# SN32F420 register map
Vendor: SONiX Technology Co., Ltd.; Series: SN32F420; File version: 1.00
CPU: CM0 r0p0, little endian, no MPU, no FPU, 2 interrupt priority bits
Registers are 32-bit, read-write, reset 0x0 unless marked. A register's access mark holds for its fields unless they carry their own. Offsets are from the block's base; [hi:lo] are bit positions.

## SN_SYS0 — System Control Registers 0
Base 0x40060000
0x00 ANBCTRL reset 0x1 — Offset:0x00 Analog Block Control register
  [0] IHRCEN — IHRC enable
    0=Disable IHRC; 1=Enable IHRC
0x04 PLLCTRL — Offset:0x04 PLL Control register
  [15] PLLEN — PLL enable
    0=Disable PLL; 1=Enable PLL
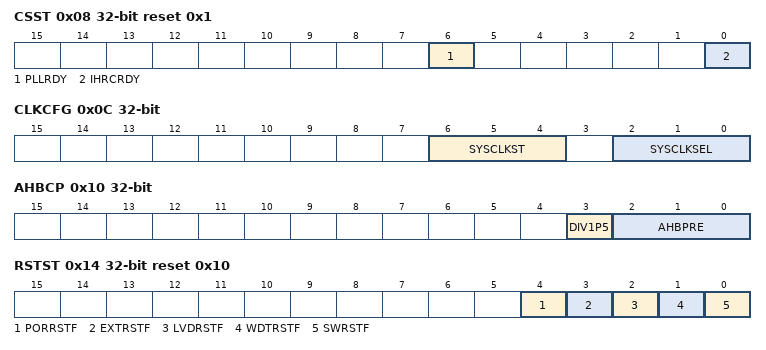
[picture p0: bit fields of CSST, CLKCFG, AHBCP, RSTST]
0x08 CSST ro reset 0x1 — Offset:0x08 Clock Source Status register
  [6] PLLRDY — PLL ready flag
    0=Not Locked (PLL is Not locked); 1=Locked (PLL is locked)
  [0] IHRCRDY — IHRC ready flag
    0=Not Ready (IHRC is Not Ready); 1=Ready (IHRC is Ready)
0x0C CLKCFG — Offset:0x0C System Clock Configuration register
  [6:4] SYSCLKST ro — System clock switch status
    0=IHRC (IHRC is used as system clock); 1=ILRC (ILRC is used as system clock); 4=PLL (PLL output is used as system clock)
  [2:0] SYSCLKSEL — System clock source selection
    0=IHRC (HCLK=IHRC); 1=ILRC (HCLK=ILRC); 4=PLL Output (HCLK=PLL output)
0x10 AHBCP — Offset:0x10 AHB Clock Prescale register
  [3] DIV1P5 — SYSCLK prescaler
    0=DIV1 (SYSCLK = SYSCLK/1); 1=DIV1P5 (SYSCLK = SYSCLK/1.5)
  [2:0] AHBPRE — AHB clock source prescaler
    0=000b (FAHB=FSYSCLK/1); 1=001b (FAHB=FSYSCLK/2); 2=010b (FAHB=FSYSCLK/4); 3=011b (FAHB=FSYSCLK/8); 4=100b (FAHB=FSYSCLK/16); 5=101b (FAHB=FSYSCLK/32); 6=110b (FAHB=FSYSCLK/64); 7=111b (FAHB=FSYSCLK/128)
0x14 RSTST reset 0x10 — Offset:0x14 System Reset Status register
  [4] PORRSTF — POR reset flag
    0=None (No POR occurred); 1=POR (POR occurred)
  [3] EXTRSTF — External reset flag
    0=None (No Extenral reset occurred); 1=External reset occurred
  [2] LVDRSTF — LVD reset flag
    0=None (No LVD reset occurred); 1=LVD reset occurred
  [1] WDTRSTF — WDT reset flag
    0=None (No WDT reset occurred); 1=WDR reset (WDT reset occurred)
  [0] SWRSTF — Software reset flag
    0=None (No SW reset occurred); 1=SW reset occurred
0x1C EXRSTCTRL reset 0x1 — Offset:0x1C External Reset Pin Control register
  [0] RESETDIS — External reset pin disable
    0=Enable (P3.6 acts as nRESET pin); 1=Disable (P3.6 acts as GPIO pin)
0x20 SWDCTRL — Offset:0x20 SWD Pin Control register
  [0] SWDDIS — SWD pin disable
    0=Enable SWD pins; 1=Disable SWD pins
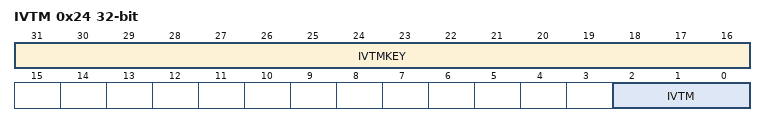
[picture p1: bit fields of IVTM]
0x24 IVTM — Offset:0x24 Interrupt Vector Table Mapping register
  [31:16] IVTMKEY wo — IVTM register key
  [2:0] IVTM — Interrupt table mapping selection
    0=000b (Map to User ROM); 1=001b (Map to User ROM); 2=010b (Map to SRAM)

## SN_FLASH — FLASH Memory Control Registers
Base 0x40062000
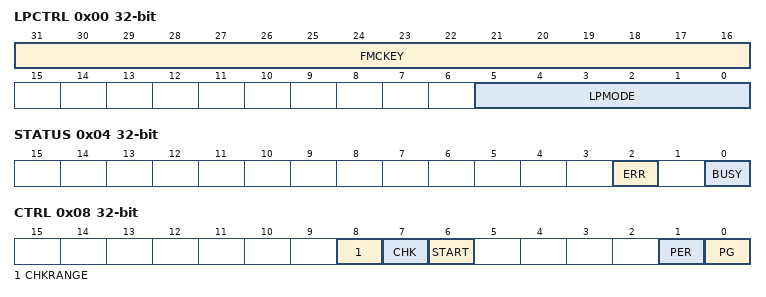
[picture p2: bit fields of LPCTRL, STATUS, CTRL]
0x00 LPCTRL — Offset:0x00 Flash Low Power Control register
  [31:16] FMCKEY wo — FMC verify key
  [5:0] LPMODE — Flash Low Power mode selection bit
    0=HCLK is less than 24MHz; 17=HCLK is more than or equal to 24MHz, and less than or equal to 48MHz
0x04 STATUS — Offset:0x04 Flash Status register
  [2] ERR — Erase/Error flag
    0=No (No error); 1=Error (The address is illegal or over page boundary)
  [0] BUSY ro — Busy flag
    0=Idle (FMC is idle); 1=Busy (Flash operation is in process)
0x08 CTRL — Offset:0x08 Flash Control register
  [8] CHKRANGE — Checksum range select bit
    0=All User ROM (0x00000000~0x00007FFF); 1=Except the last 64 bytes (Calculate User ROM, except the last 64 bytes. (0x00000000~0x00007FBF))
  [7] CHK — Checksum calculation chosen
    0=Disable checksum calcuation; 1=Enable (Trigger checksum calculation)
  [6] START — Start erase/program operation
    0=Stop/finish operation; 1=Start erase/program operation
  [1] PER — Page erase mode chosen bit
    0=Disable page erase mode; 1=Enable page erase mode
  [0] PG — Flash program mode chosen bit
    0=Disable Flash program mode; 1=Enable Flash program mode
0x0C DATA — Offset:0x0C Flash Data register
  [31:0] DATA — Flash data
0x10 ADDR — Offset:0x10 Flash Address register
  [31:0] ADDR — Flash address
0x14 CHKSUM ro — Offset:0x14 Flash Checksum register
  [15:0] UserROM — Checksum of User ROM
0x20 WP — Offset:0x20 Flash Write Protect register
  [15:0] WP — Flash Write protect key
